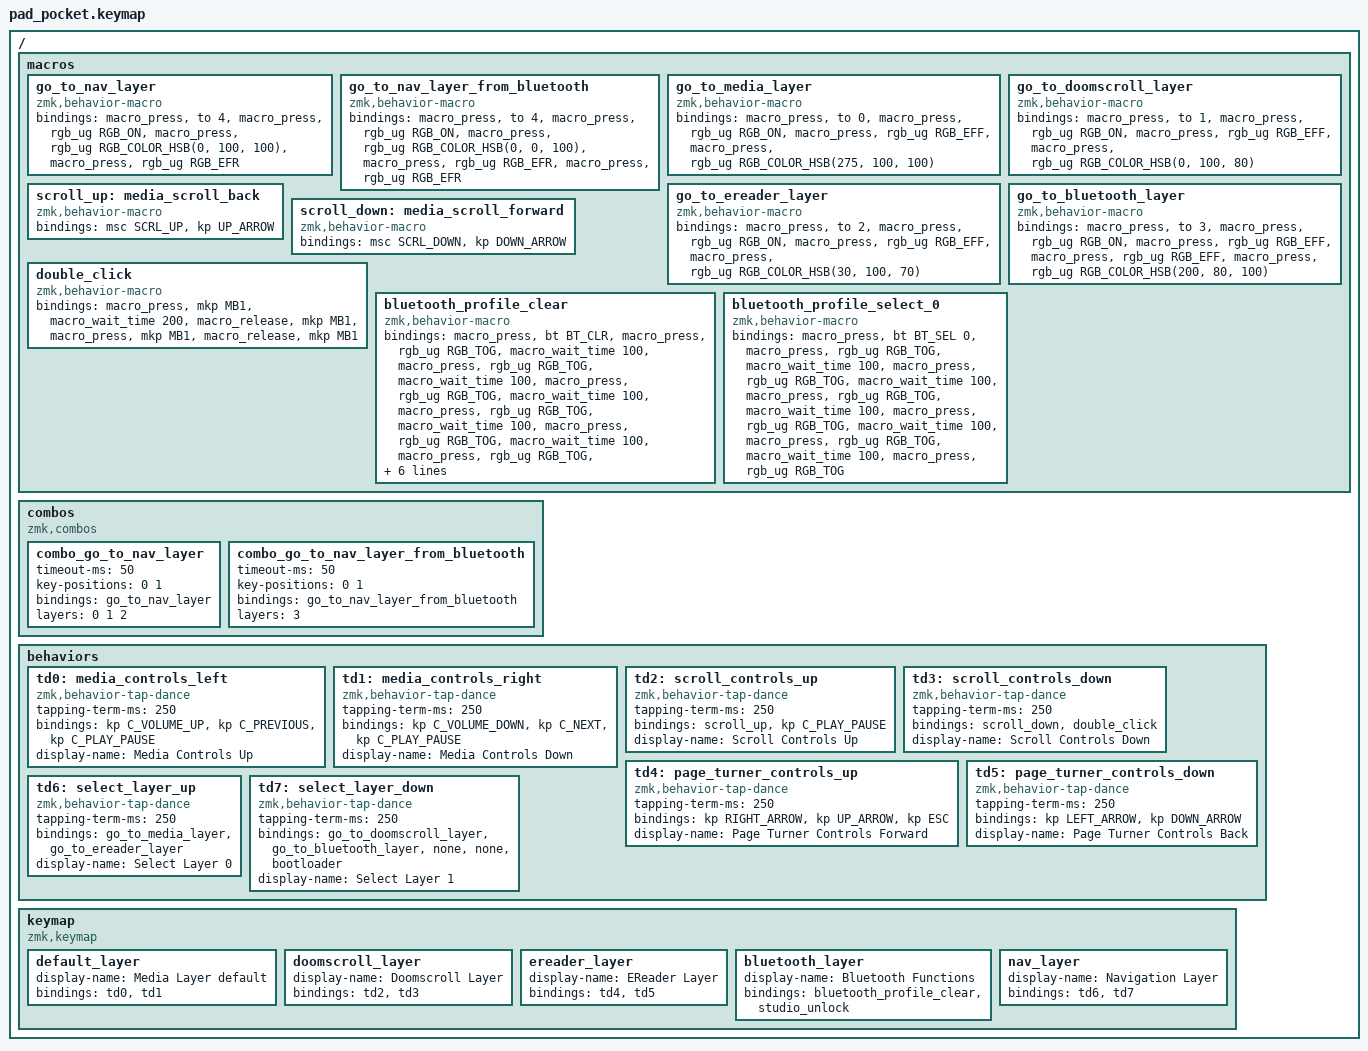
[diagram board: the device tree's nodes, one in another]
#include <behaviors.dtsi>
#include <dt-bindings/zmk/keys.h>
#include <dt-bindings/zmk/bt.h>
#include <dt-bindings/zmk/rgb.h>
#include <dt-bindings/zmk/pointing.h>

#define ZMK_POINTING_DEFAULT_SCRL_VAL 5

/ {
     macros {
        go_to_nav_layer: go_to_nav_layer {
            compatible = "zmk,behavior-macro";
            #binding-cells = <0>;
            // spinning rainbow
            bindings = <&macro_press &to 4>, <&macro_press &rgb_ug RGB_ON>, <&macro_press &rgb_ug RGB_COLOR_HSB(0, 100, 100)>, <&macro_press &rgb_ug RGB_EFR>;
        };

        go_to_nav_layer_from_bluetooth: go_to_nav_layer_from_bluetooth {
            compatible = "zmk,behavior-macro";
            #binding-cells = <0>;
            // spinning rainbow
            bindings = <&macro_press &to 4>, <&macro_press &rgb_ug RGB_ON>, <&macro_press &rgb_ug RGB_COLOR_HSB(0, 0, 100)>, <&macro_press &rgb_ug RGB_EFR>, <&macro_press &rgb_ug RGB_EFR>;
        };

        go_to_media_layer: go_to_media_layer {
            compatible = "zmk,behavior-macro";
            #binding-cells = <0>;
            // solid purple
            bindings = <&macro_press &to 0>, <&macro_press &rgb_ug RGB_ON>, <&macro_press &rgb_ug RGB_EFF>, <&macro_press &rgb_ug RGB_COLOR_HSB(275, 100, 100)>; 
        };

        go_to_doomscroll_layer: go_to_doomscroll_layer {
            compatible = "zmk,behavior-macro";
            #binding-cells = <0>;
            // solid red
            bindings = <&macro_press &to 1>, <&macro_press &rgb_ug RGB_ON>, <&macro_press &rgb_ug RGB_EFF>, <&macro_press &rgb_ug RGB_COLOR_HSB(0, 100, 80)>;
        };

        go_to_ereader_layer: go_to_ereader_layer {
            compatible = "zmk,behavior-macro";
            #binding-cells = <0>;
            // solid yellow
            bindings = <&macro_press &to 2>, <&macro_press &rgb_ug RGB_ON>, <&macro_press &rgb_ug RGB_EFF>, <&macro_press &rgb_ug RGB_COLOR_HSB(30, 100, 70)>;
        };

        go_to_bluetooth_layer: go_to_bluetooth_layer {
            compatible = "zmk,behavior-macro";
            #binding-cells = <0>;
            // blue breathing
            bindings = <&macro_press &to 3>, <&macro_press &rgb_ug RGB_ON>, <&macro_press &rgb_ug RGB_EFF>, <&macro_press &rgb_ug RGB_EFF>, <&macro_press &rgb_ug RGB_COLOR_HSB(200, 80, 100)>; 
        };

        scroll_up: media_scroll_back {
            compatible = "zmk,behavior-macro";
            #binding-cells = <0>;
            bindings = <&msc SCRL_UP>, <&kp UP_ARROW>;
        };

        scroll_down: media_scroll_forward {
            compatible = "zmk,behavior-macro";
            #binding-cells = <0>;
            bindings = <&msc SCRL_DOWN>, <&kp DOWN_ARROW>;
        };

        double_click: double_click {
            compatible = "zmk,behavior-macro";
            #binding-cells = <0>;
            bindings = <&macro_press &mkp MB1>, <&macro_wait_time 200>, <&macro_release &mkp MB1>, <&macro_press &mkp MB1>, <&macro_release &mkp MB1>; 
        };

        bluetooth_profile_clear: bluetooth_profile_clear {
            compatible = "zmk,behavior-macro";
            #binding-cells = <0>;
            bindings = <&macro_press &bt BT_CLR>
            , <&macro_press &rgb_ug RGB_TOG>
            , <&macro_wait_time 100>
            , <&macro_press &rgb_ug RGB_TOG>
            ,  <&macro_wait_time 100>
            , <&macro_press &rgb_ug RGB_TOG>
            , <&macro_wait_time 100>
            , <&macro_press &rgb_ug RGB_TOG>
            , <&macro_wait_time 100>
            , <&macro_press &rgb_ug RGB_TOG>
            , <&macro_wait_time 100>
            , <&macro_press &rgb_ug RGB_TOG>
            , <&macro_wait_time 100>
            , <&macro_press &rgb_ug RGB_TOG>
            , <&macro_wait_time 100>
            , <&macro_press &rgb_ug RGB_TOG>
            , <&macro_wait_time 100>
            , <&macro_press &rgb_ug RGB_TOG>
            , <&macro_wait_time 100>
            , <&macro_press &rgb_ug RGB_TOG>; 
        };

        bluetooth_profile_select_0: bluetooth_profile_select_0 {
            compatible = "zmk,behavior-macro";
            #binding-cells = <0>;
            bindings = <&macro_press &bt BT_SEL 0>
            , <&macro_press &rgb_ug RGB_TOG>
            , <&macro_wait_time 100>
            , <&macro_press &rgb_ug RGB_TOG>
            , <&macro_wait_time 100>
            , <&macro_press &rgb_ug RGB_TOG>
            , <&macro_wait_time 100>
            , <&macro_press &rgb_ug RGB_TOG>
            , <&macro_wait_time 100>
            , <&macro_press &rgb_ug RGB_TOG>
            , <&macro_wait_time 100>
            , <&macro_press &rgb_ug RGB_TOG>; 
        };
    };

    combos {
        compatible = "zmk,combos";

        combo_go_to_nav_layer {
            timeout-ms = <50>;
            key-positions = <0 1>;
            bindings = <&go_to_nav_layer>;
            layers = <0 1 2>; // only works from regular layers
        };

        combo_go_to_nav_layer_from_bluetooth {
            timeout-ms = <50>;
            key-positions = <0 1>;
            bindings = <&go_to_nav_layer_from_bluetooth>;
            layers = <3>; // only works from bluetooth layer (layer 3)
        };
    };

    behaviors {
        // stops working if you rename it media_controls_up, no idea why
        td0: media_controls_left {
            compatible = "zmk,behavior-tap-dance";
            #binding-cells = <0>;
            tapping-term-ms = <250>;
            bindings = <&kp C_VOLUME_UP>, <&kp C_PREVIOUS>, <&kp C_PLAY_PAUSE>;
            display-name = "Media Controls Up";
        };

        td1: media_controls_right {
            compatible = "zmk,behavior-tap-dance";
            #binding-cells = <0>;
            tapping-term-ms = <250>;
            bindings = <&kp C_VOLUME_DOWN>, <&kp C_NEXT>, <&kp C_PLAY_PAUSE>;
            display-name = "Media Controls Down";
        };

        td2: scroll_controls_up {
            compatible = "zmk,behavior-tap-dance";
            #binding-cells = <0>;
            tapping-term-ms = <250>;
            bindings = <&scroll_up>, <&kp C_PLAY_PAUSE>;
            display-name = "Scroll Controls Up";
        };

        td3: scroll_controls_down {
            compatible = "zmk,behavior-tap-dance";
            #binding-cells = <0>;
            tapping-term-ms = <250>;
            bindings = <&scroll_down>, <&double_click>;
            display-name = "Scroll Controls Down";
        };

        td4: page_turner_controls_up {
            compatible = "zmk,behavior-tap-dance";
            #binding-cells = <0>;
            tapping-term-ms = <250>;
            bindings = <&kp RIGHT_ARROW>, <&kp UP_ARROW>, <&kp ESC>;
            display-name = "Page Turner Controls Forward";
        };

        td5: page_turner_controls_down {
            compatible = "zmk,behavior-tap-dance";
            #binding-cells = <0>;
            tapping-term-ms = <250>;
            bindings = <&kp LEFT_ARROW>, <&kp DOWN_ARROW>;
            display-name = "Page Turner Controls Back";
        };

        td6: select_layer_up {
            compatible = "zmk,behavior-tap-dance";
            #binding-cells = <0>;
            tapping-term-ms = <250>;
            bindings = <
                &go_to_media_layer
                &go_to_ereader_layer
            >;
            display-name = "Select Layer 0";
        };

        td7: select_layer_down {
            compatible = "zmk,behavior-tap-dance";
            #binding-cells = <0>;
            tapping-term-ms = <250>;
            bindings = <
                &go_to_doomscroll_layer
                &go_to_bluetooth_layer
                &none
                &none
                &bootloader
            >;
            display-name = "Select Layer 1";
        };
    };

    keymap {
        compatible = "zmk,keymap";

        // Layer 0 - Media Layer (default)
        // Solid purple
        default_layer {
            display-name= "Media Layer default";
            // ----------------
            // |     Vol +    |
            // |     Vol -    |
            // ----------------
            bindings = <
                &td0
                &td1
            >;
        };

        // Layer 1 - Doomscroll Layer
        // Solid red
        doomscroll_layer {
            display-name= "Doomscroll Layer";
            // ----------------
            // |   Scroll Up  |
            // |  Scroll Down |
            // ----------------
            bindings = <
                &td2
                &td3
            >;
        };

        // Layer 2 - EReader Layer
        // Solid yellow
        ereader_layer {
            display-name= "EReader Layer";
            // ----------------
            // | Page Forward | 
            // |   Page Back  |
            // ----------------
            bindings = <
                &td4
                &td5
            >;
        };

        // Layer 3 - Bluetooth Layer
        // Breathing blue
        bluetooth_layer {
            display-name = "Bluetooth Functions";
            // -----------------
            // |    BT Clear   |
            // | Studio Unlock |
            // ----------------
            bindings = <
                &bluetooth_profile_clear
                &studio_unlock
            >;
        };

        // Layer 4 - Navigation Layer
        // Rotating rainbow
        nav_layer {
            display-name= "Navigation Layer";
            // ----------------
            // |     Nav 0    |
            // |     Nav 1    |
            // ----------------
            bindings = <
                &td6
                &td7
            >;
        };

    };
 };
